# ATA5702M322 device description
Architecture: AVR8; Family: megaAVR
Registers are 8-bit, access not given, no defined reset value unless marked. A register's access mark holds for its fields unless they carry their own. Offsets are from the block's base; [hi:lo] are bit positions; {n}, {i} and the like mark numbered series.

## CRC
Instances: CRC 0x00
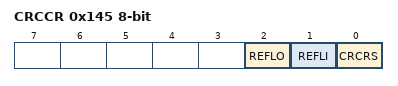
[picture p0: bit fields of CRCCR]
0x145 CRCCR — CRC Control Register
  [2] REFLO — Reflect Data Output Byte
  [1] REFLI — Reflect Data Input Byte
  [0] CRCRS — CRC Data Register Reset
0x146 CRCDOR — CRC Data Output Register
0x1E0 CRCDIR — CRC Data Input Register

## DEBOUNCE
Instances: DEBOUNCE 0x00
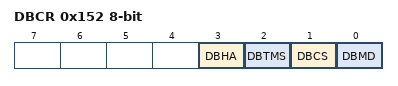
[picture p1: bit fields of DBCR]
0x152 DBCR — DeBounce Control Register
  [3] DBHA — Debounce Handshake Active
  [2] DBTMS — Debounce Timer Mask Select
  [1] DBCS — Debounce Clock Select
  [0] DBMD — Debounce Mode
0x153 DBTC — Debounce Timer Compare Register
0x154 DBENB — DeBounce Enable Port B
0x155 DBENC bits used 2:0 — DeBounce Enable Port C
0x164 DBEND — DeBounce Enable Port D

## DEBUG
Instances: DEBUG 0x00
0xFC TRCID 16-bit — Trace ID Register
0xFF TRCDR — Trace Data Register
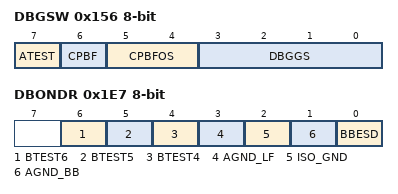
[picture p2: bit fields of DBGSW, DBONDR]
0x156 DBGSW — Debugging Support Switch
  [7] ATEST — Analog Test Pins Enable
  [6] CPBF — CPU Busy Flag
  [5:4] CPBFOS — CPU Busy Flag Output Select
    0=disabled; 1=PB0; 2=PB3; 3=PC1
  [3:0] DBGGS — Debugging Support Group Select
0x1E7 DBONDR — Downbond Test Register
  [6] BTEST6 — Bond Test 6
  [5] BTEST5 — Bond Test 5
  [4] BTEST4 — Bond Test 4
  [3] AGND_LF — Bond AGND LF
  [2] ISO_GND — Bond ISO SUBS3 GND
  [1] AGND_BB — Bond AGND BB
  [0] BBESD — Bond BBESD

## DFIFO
Instances: DFIFO 0x00
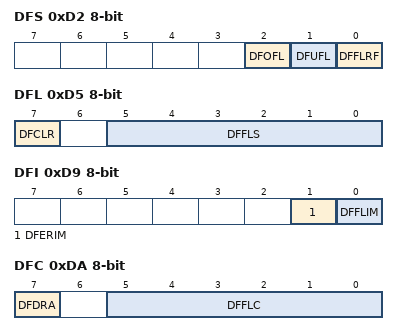
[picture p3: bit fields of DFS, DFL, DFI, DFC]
0xD2 DFS — Data FIFO Status Register
  [2] DFOFL — Data FIFO Overflow Flag
  [1] DFUFL — Data FIFO Underflow Flag
  [0] DFFLRF — Data FIFO Fill-Level Reached Status Flag
0xD5 DFL — Data FIFO Fill Level Register
  [7] DFCLR — Data FIFO Clear
  [5:0] DFFLS — Data FIFO Fill Level Status
0xD6 DFWP bits used 5:0 — Data FIFO Write Pointer
0xD7 DFRP bits used 5:0 — Data FIFO Read Pointer
0xD8 DFD — Data FIFO Data Register
0xD9 DFI — Data FIFO Interrupt Mask Register
  [1] DFERIM — Data FIFO Error Interrupt Mask
  [0] DFFLIM — Data FIFO Fill-level Interrupt Mask
0xDA DFC — Data FIFO Configuration Register
  [7] DFDRA — Data FIFO Direct Read Access Operational Mode
  [5:0] DFFLC — Data FIFO Fill-Level Configuration

## EEPROM
Instances: EEPROM 0x00
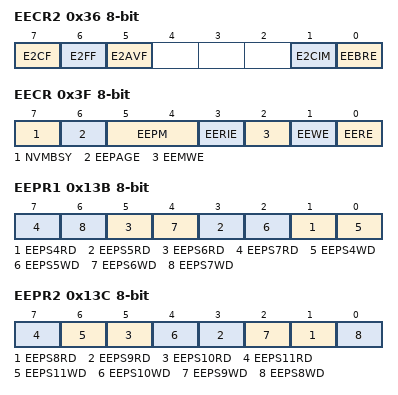
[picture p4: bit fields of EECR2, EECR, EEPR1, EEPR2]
0x36 EECR2 — EEPROM Control Register 2
  [7] E2CF — EEPROM Error Correction Code Flag
  [6] E2FF — EEPROM error Fault Flag bit
  [5] E2AVF — EEPROM Access Violation Flag
  [1] E2CIM — EEPROM Error Code Correction Interrupt Mask
  [0] EEBRE — EEPROM Burst Read Enable
0x3F EECR — EEPROM Control Register
  [7] NVMBSY — Non-volatile memory busy
  [6] EEPAGE — EEPROM page access (multiple bytes access mode)
  [5:4] EEPM — EEPROM Programming Mode
    0=Erase and Write in one operation; 1=Erase Only; 2=Write Only
  [3] EERIE — EEPROM Ready Interrupt Enable
  [2] EEMWE — EEPROM Master Write Enable
  [1] EEWE — EEPROM Write Enable
  [0] EERE — EEPROM Read Enable
0x40 EEDR — EEPROM Data Register
0x41 EEAR 16-bit bits used 11:0 — EEPROM Address Register
0x43 EEPR — EEPROM Protection Register
  [3:0] EEAP — EEPROM Access Protection
0x13B EEPR1 — EEPROM Protection Register 1
  [2n-7] EEPS{n}RD (n=4..7) — EEPROM Protection Section {n} Read Disable
  [2n-8] EEPS{n}WD (n=4..7) — EEPROM Protection Section {n} Write Disable
0x13C EEPR2 — EEPROM Protection Register 2
  [2n-15] EEPS{n}RD (n=8..11) — EEPROM Protection Section {n} Read Disable
  [6] EEPS11WD — EEPROM Protection Section 11 Write Disable
  [4] EEPS10WD — EEPROM Protection Section 10 Write Disableble
  [2] EEPS9WD — EEPROM Protection Section 9 Write Disable
  [0] EEPS8WD — EEPROM Protection Section 8 Write Disable
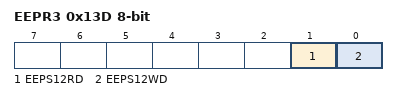
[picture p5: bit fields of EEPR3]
0x13D EEPR3 — EEPROM Protection Register 3
  [1] EEPS12RD — EEPROM Protection Section 12 Read Disable
  [0] EEPS12WD — EEPROM Protection Section 12 Write Disable

## FE
Instances: FE 0x00
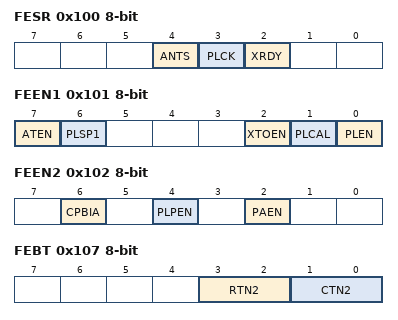
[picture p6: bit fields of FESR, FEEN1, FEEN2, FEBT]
0x100 FESR — Front-End Status Register
  [4] ANTS — Antenna saturated
  [3] PLCK — PLL locked
  [2] XRDY — XTO ready
0x101 FEEN1 — Front-End Enable Register 1
  [7] ATEN — Antenna Tuning Enable
  [6] PLSP1 — PLL Speedup 1
  [2] XTOEN — Cristal Oscillator enable
  [1] PLCAL — PLL calibration mode
  [0] PLEN — PLL enable
0x102 FEEN2 — Front-End Enable Register 2
  [6] CPBIA — Cap Array Bias
  [4] PLPEN — PLL Post En IQ divider
  [2] PAEN — Power Amplifier enable
0x103 FELNA — Reserved
0x104 FEAT — Front-End Antenna Tuning
  [3:0] ANTN — Antenna Tuning
0x105 FEPAC — Front-End Power Amplifier Control Register
  [7:0] PACR — Front-End Power Amplifier Control Register Pout/dBm LowBand HighBand
    0=-11.80 -12.90; 1=-11.30 -12.33; 2=-10.70 -11.76; 3=-10.20 -11.10; 4=-9.70 -10.60; 5=-9.20 -10.00; 6=-8.60 -9.50; 7=-8.00 -9.00; 8=-7.50 -8.50; 9=-7.00 -7.90; 10=-6.40 -7.30; 11=-5.90 -6.80; 12=-5.30 -6.30; 13=-4.77 -5.70; 14=-4.17 -5.20; 15=-3.67 -4.60; 16=-3.12 -4.07; 17=-2.56 -3.47; 18=-2.10 -2.97; 19=-1.58 -2.42; 20=-1.08 -1.86; 21=-0.50 -1.40; 22=0.00 -0.88; 23=0.41 -0.38; 24=1.00 0.20; 25=1.42 0.70; 26=1.83 1.11; 27=2.42 1.70; 28=2.88 2.12; 29=3.38 2.53; 30=3.81 3.12; 31=4.31 3.58; 32=4.72 4.08; 33=5.09 4.51; 34=5.57 5.01; 35=6.00 5.42; 36=6.41 5.79; 37=6.77 6.27; 38=7.19 6.70; 39=7.55 7.11; 40=7.98 7.47; 41=8.40 7.89; 42=8.79 8.25; 43=9.11 8.68; 44=9.46 9.10; 45=9.82 9.49; 46=10.18 9.81; 47=10.60 10.16; 48=10.89 10.52; 49=11.30 10.88; 50=11.62 11.30; 51=12.06 11.59; 52=12.39 12.00; 53=12.82 12.32; 54=13.22 12.76; 55=13.58 13.09; 56=13.95 13.52; 57=14.22 13.92; 58=14.41 14.28; 59=14.49 14.65; {v}=14.60 14.65 (v=60..63)
0x106 FEVCT bits used 3:0 — Front-End VCO Tuning Register
0x107 FEBT — Front-End RC Tuning Register
  [3:2] RTN2 — Resistor Tuning
  [1:0] CTN2 — Capacitor Tuning
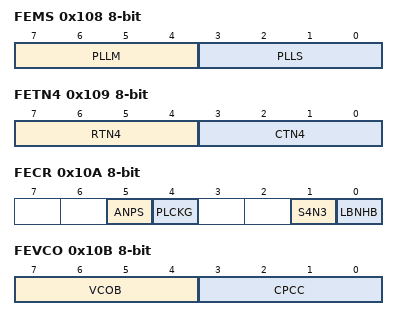
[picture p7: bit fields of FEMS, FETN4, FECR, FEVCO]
0x108 FEMS — Front-End Main and Swallow Control Register
  [7:4] PLLM — PLL Mode
  [3:0] PLLS — PLL Swallow
0x109 FETN4 — Front-End RC Tuning 4bit Register
  [7:4] RTN4 — 4 bit Resistor Tuning
  [3:0] CTN4 — 4 bit Capacitor Tuning
0x10A FECR — Front-End Control Register
  [5] ANPS — ASK Not DPSK Switch
  [4] PLCKG — PLL Lock Detect Gate
  [1] S4N3 — Select 433 Not 315MHz Band
  [0] LBNHB — Select Low-Band Not High-Band
0x10B FEVCO — Front-End VCO and PLL control
  [7:4] VCOB — VCO Bias
  [3:0] CPCC — Charge pump current control
0x10C FEALR — Front-End Antenna Level Detector Range
  [1:0] RNGE — Range of the ANT_TUNE level detector
    0=0..3 dBm; 1=4..7 dBm; 2=8..14 dBm; 3=Secure Measurement
0x10D FEANT — Front-End Antenna
  [3:0] LVLC — antenna signal LeVeL
0x10E FEBIA — Reserved
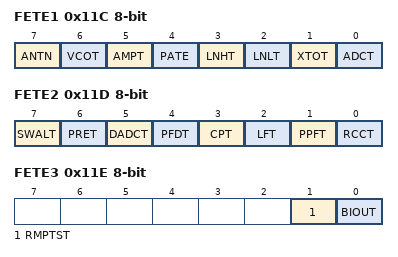
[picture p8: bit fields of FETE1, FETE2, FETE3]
0x11C FETE1 — Front-End Test Enable Register 1
  [7] ANTN, [6] VCOT, [5] AMPT, [4] PATE, [3] LNHT, [2] LNLT, [1] XTOT, [0] ADCT
0x11D FETE2 — Front-End Test Enable Register 2
  [7] SWALT, [6] PRET, [5] DADCT, [4] PFDT, [3] CPT, [2] LFT, [1] PPFT, [0] RCCT
0x11E FETE3 — Front-End Test Enable Register 3
  [1] RMPTST, [0] BIOUT
0x11F FETD — Front-End Test Data Register
